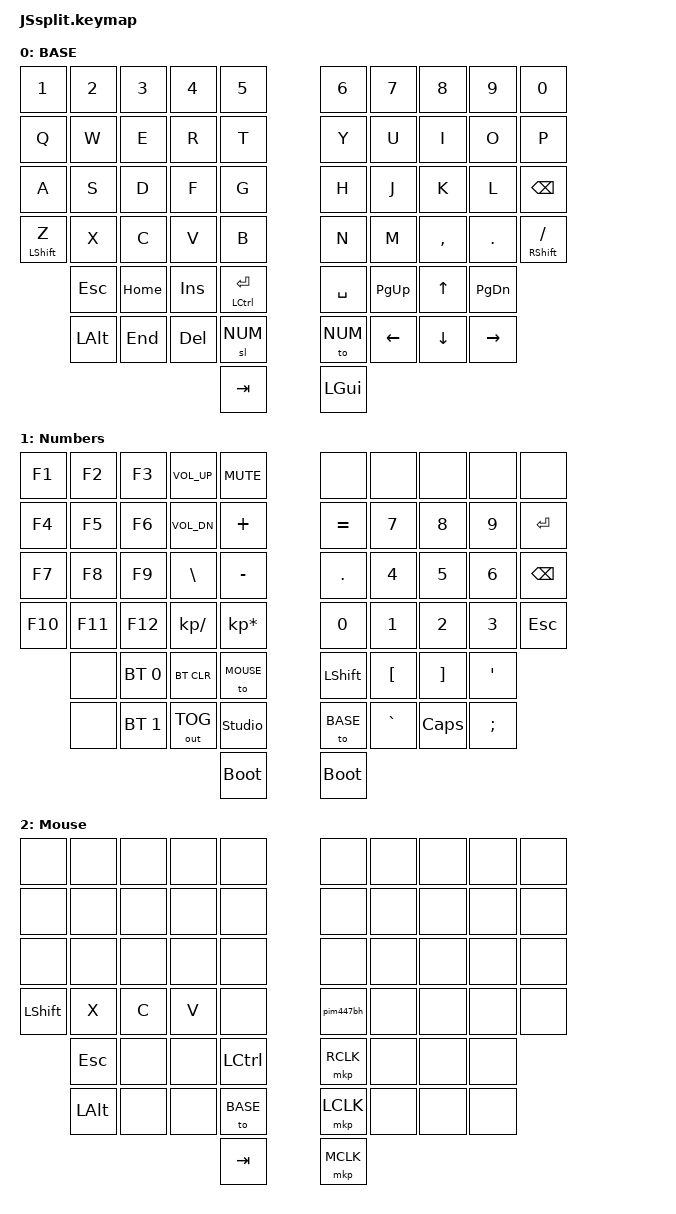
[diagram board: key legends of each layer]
#include <behaviors.dtsi>
#include <input/processors.dtsi>
#include <dt-bindings/zmk/keys.h>
#include <dt-bindings/zmk/bt.h>
#include <dt-bindings/zmk/outputs.h>
#include <dt-bindings/zmk/pointing.h>
#include <dt-bindings/zmk/mouse.h>
#include <dt-bindings/behavior_pim447.h>
//Need this include above for My Driver and not for New Driver (3-1-2026)

#define BASE 0
#define NUM 1
#define MOUSE 2
#define extra2 3

#define COMBO_TIME_OUT 25

/ {
    

   // My Driver -- pre 3-1-2026
   behaviors {
        pim447bh: pim447bh {
            compatible = "zmk,behavior-pim447";
            #binding-cells = <1>;
            action = <14>;
            
        };
        
    };

    /*
    //New Driver -- 3-1-2026
    behaviors {
        tb_mode: trackball_mode {
            compatible = "zmk,behavior-trackball-mode";
            #binding-cells = <1>;
            
            default-mode = <0>;    // 0=move, 1=scroll
            
            // Optional LED colors for each mode (see trackball_pim447.h)
            led-mode-move = <2>;   // Green (LED_GREEN) 
            led-mode-scroll = <3>; // Blue (LED_BLUE)
        };
    };
    */

    keymap {
        compatible = "zmk,keymap";

        /* Qwerty
        ┏━━━━━━━━━┳━━━━━━━━━┳━━━━━━━━━┳━━━━━━━━━┳━━━━━━━━━┓          ┏━━━━━━━━━┳━━━━━━━━━┳━━━━━━━━━┳━━━━━━━━━┳━━━━━━━━━┓
        ┃   1 !   ┃   2 @   ┃    3    ┃    4    ┃    5    ┃          ┃    6    ┃    7    ┃    8    ┃    9    ┃    0    ┃
        ┣━━━━━━━━━╋━━━━━━━━━╋━━━━━━━━━╋━━━━━━━━━╋━━━━━━━━━┫          ┣━━━━━━━━━╋━━━━━━━━━╋━━━━━━━━━╋━━━━━━━━━╋━━━━━━━━━┫
        ┃    Q    ┃    W    ┃    E    ┃    R    ┃    T    ┃          ┃    Y    ┃    U    ┃    I    ┃    O    ┃    P    ┃
        ┣━━━━━━━━━╋━━━━━━━━━╋━━━━━━━━━╋━━━━━━━━━╋━━━━━━━━━┫          ┣━━━━━━━━━╋━━━━━━━━━╋━━━━━━━━━╋━━━━━━━━━╋━━━━━━━━━┫
        ┃    A    ┃    S    ┃    D    ┃    F    ┃    G    ┃          ┃    H    ┃    J    ┃    K    ┃    L    ┃   BSPC  ┃
        ┣━━━━━━━━━╋━━━━━━━━━╋━━━━━━━━━╋━━━━━━━━━╋━━━━━━━━━┫          ┣━━━━━━━━━╋━━━━━━━━━╋━━━━━━━━━╋━━━━━━━━━╋━━━━━━━━━┫
        ┃SHIFT  Z ┃    X    ┃    C    ┃    V    ┃    B    ┃          ┃    N    ┃    M    ┃    ,    ┃    .    ┃SHIFT /  ┃
        ┗━━━━━━━━━╋━━━━━━━━━╋━━━━━━━━━╋━━━━━━━━━╋━━━━━━━━━┫          ┣━━━━━━━━━╋━━━━━━━━━╋━━━━━━━━━╋━━━━━━━━━╋━━━━━━━━━┛
                  ┃  WIN    ┃  HOME   ┃   INS   ┃CTRL/ENTR┃          ┃  SPACE  ┃  PG_UP  ┃    UP   ┃  PG_DN  ┃
                  ┣━━━━━━━━━╋━━━━━━━━━╋━━━━━━━━━╋━━━━━━━━━┫          ┣━━━━━━━━━╋━━━━━━━━━╋━━━━━━━━━╋━━━━━━━━━┫
                  ┃  LALT   ┃   END   ┃   DEL   ┃ TempNUM ┃          ┃ TO NUM  ┃   LEFT  ┃   DOWN  ┃  RIGHT  ┃
                  ┗━━━━━━━━━┻━━━━━━━━━┻━━━━━━━━━┣━━━━━━━━━┫          ┣━━━━━━━━━┫━━━━━━━━━┻━━━━━━━━━┻━━━━━━━━━┛
                                                ┃   TAB   ┃          ┃   ESC   ┃
                                                ┗━━━━━━━━━┛          ┗━━━━━━━━━┛
        */

        base {
            label = "BASE";
            bindings = <
                &kp N1      &kp N2      &kp N3          &kp N4          &kp N5                              &kp N6      &kp N7          &kp N8          &kp N9          &kp N0
                &kp Q       &kp W       &kp E           &kp R           &kp T                               &kp Y       &kp U           &kp I           &kp O           &kp P
                &kp A       &kp S       &kp D           &kp F           &kp G                               &kp H       &kp J           &kp K           &kp L           &kp BSPC
                &mt LSHFT Z &kp X       &kp C           &kp V           &kp B                               &kp N       &kp M           &kp COMMA       &kp DOT         &mt RSHFT FSLH
                            &kp ESC     &kp HOME        &kp INSERT      &mt LCTRL ENTER                     &kp SPACE   &kp PG_UP       &kp UP_ARROW    &kp PG_DN
                            &kp LALT    &kp END         &kp DELETE      &sl NUM                             &to NUM     &kp LEFT_ARROW  &kp DOWN_ARROW  &kp RIGHT_ARROW
                                                                        &kp TAB                             &kp LGUI
            >;
        };

        /* Numbers
        ┏━━━━━━━━━┳━━━━━━━━━┳━━━━━━━━━┳━━━━━━━━━┳━━━━━━━━━┓          ┏━━━━━━━━━┳━━━━━━━━━┳━━━━━━━━━┳━━━━━━━━━┳━━━━━━━━━┓
        ┃    F1   ┃    F2   ┃   F3    ┃  VOL+   ┃   MUTE  ┃          ┃  NONE   ┃  NONE   ┃  NONE   ┃  NONE   ┃  NONE   ┃
        ┣━━━━━━━━━╋━━━━━━━━━╋━━━━━━━━━╋━━━━━━━━━╋━━━━━━━━━┫          ┣━━━━━━━━━╋━━━━━━━━━╋━━━━━━━━━╋━━━━━━━━━╋━━━━━━━━━┫
        ┃    F4   ┃    F5   ┃    F6   ┃  VOL-   ┃    +    ┃          ┃   = +   ┃    7    ┃    8    ┃    9    ┃  ENTER  ┃
        ┣━━━━━━━━━╋━━━━━━━━━╋━━━━━━━━━╋━━━━━━━━━╋━━━━━━━━━┫          ┣━━━━━━━━━╋━━━━━━━━━╋━━━━━━━━━╋━━━━━━━━━╋━━━━━━━━━┫
        ┃    F7   ┃    F8   ┃    F9   ┃   \ |   ┃  - _    ┃          ┃    .    ┃    4    ┃    5    ┃    6    ┃   BSPC  ┃
        ┣━━━━━━━━━╋━━━━━━━━━╋━━━━━━━━━╋━━━━━━━━━╋━━━━━━━━━┫          ┣━━━━━━━━━╋━━━━━━━━━╋━━━━━━━━━╋━━━━━━━━━╋━━━━━━━━━┫
        ┃   F10   ┃   F11   ┃   F12   ┃    /    ┃    *    ┃          ┃    0    ┃    1    ┃    2    ┃    3    ┃   ESC   ┃
        ┗━━━━━━━━━╋━━━━━━━━━╋━━━━━━━━━╋━━━━━━━━━╋━━━━━━━━━┫          ┣━━━━━━━━━╋━━━━━━━━━╋━━━━━━━━━╋━━━━━━━━━╋━━━━━━━━━┛
                  ┃  NONE   ┃  NONE   ┃  NONE   ┃ TO BASE ┃          ┃  SHIFT  ┃   {     ┃     }   ┃    '    ┃
                  ┣━━━━━━━━━╋━━━━━━━━━╋━━━━━━━━━╋━━━━━━━━━┫          ┣━━━━━━━━━╋━━━━━━━━━╋━━━━━━━━━╋━━━━━━━━━┫
                  ┃  NONE   ┃  NONE   ┃  NONE   ┃  STUDIO ┃          ┃   BASE  ┃   ` ~   ┃   CAPS  ┃    ;    ┃
                  ┗━━━━━━━━━┻━━━━━━━━━┻━━━━━━━━━┣━━━━━━━━━┫          ┣━━━━━━━━━┫━━━━━━━━━┻━━━━━━━━━┻━━━━━━━━━┛
                                                ┃  BOOT   ┃          ┃   BOOT  ┃
                                                ┗━━━━━━━━━┛          ┗━━━━━━━━━┛
        */

        number {
            label = "Numbers";
            bindings = <
                &kp F1  &kp F2      &kp F3          &kp C_VOL_UP    &kp C_MUTE                          &none       &none           &none           &none           &none
                &kp F4  &kp F5      &kp F6          &kp C_VOL_DN    &kp PLUS                            &kp EQUAL   &kp N7          &kp N8          &kp N9          &kp ENTER
                &kp F7  &kp F8      &kp F9          &kp BSLH        &kp MINUS                           &kp DOT     &kp N4          &kp N5          &kp N6          &kp BSPC
                &kp F10 &kp F11     &kp F12         &kp KP_SLASH    &kp KP_ASTERISK                     &kp N0      &kp N1          &kp N2          &kp N3          &kp ESC
                        &none       &bt BT_SEL 0    &bt BT_CLR      &to MOUSE                           &kp LSHIFT  &kp LBKT        &kp RBKT        &kp SQT
                        &none       &bt BT_SEL 1    &out OUT_TOG    &studio_unlock                      &to BASE    &kp GRAVE       &kp CAPS        &kp SEMI
                                                                    &bootloader                         &bootloader
            >;
        };

        /* Mouse
        ┏━━━━━━━━━┳━━━━━━━━━┳━━━━━━━━━┳━━━━━━━━━┳━━━━━━━━━┓          ┏━━━━━━━━━┳━━━━━━━━━┳━━━━━━━━━┳━━━━━━━━━┳━━━━━━━━━┓
        ┃    F1   ┃    F2   ┃   F3    ┃  VOL+   ┃   MUTE  ┃          ┃  NONE   ┃  NONE   ┃  NONE   ┃  NONE   ┃  NONE   ┃
        ┣━━━━━━━━━╋━━━━━━━━━╋━━━━━━━━━╋━━━━━━━━━╋━━━━━━━━━┫          ┣━━━━━━━━━╋━━━━━━━━━╋━━━━━━━━━╋━━━━━━━━━╋━━━━━━━━━┫
        ┃    F4   ┃    F5   ┃    F6   ┃  VOL-   ┃    +    ┃          ┃   = +   ┃    7    ┃    8    ┃    9    ┃  ENTER  ┃
        ┣━━━━━━━━━╋━━━━━━━━━╋━━━━━━━━━╋━━━━━━━━━╋━━━━━━━━━┫          ┣━━━━━━━━━╋━━━━━━━━━╋━━━━━━━━━╋━━━━━━━━━╋━━━━━━━━━┫
        ┃    F7   ┃    F8   ┃    F9   ┃   \ |   ┃  - _    ┃          ┃    .    ┃    4    ┃    5    ┃    6    ┃   BSPC  ┃
        ┣━━━━━━━━━╋━━━━━━━━━╋━━━━━━━━━╋━━━━━━━━━╋━━━━━━━━━┫          ┣━━━━━━━━━╋━━━━━━━━━╋━━━━━━━━━╋━━━━━━━━━╋━━━━━━━━━┫
        ┃   F10   ┃   F11   ┃   F12   ┃    /    ┃    *    ┃          ┃    0    ┃    1    ┃    2    ┃    3    ┃   ESC   ┃
        ┗━━━━━━━━━╋━━━━━━━━━╋━━━━━━━━━╋━━━━━━━━━╋━━━━━━━━━┫          ┣━━━━━━━━━╋━━━━━━━━━╋━━━━━━━━━╋━━━━━━━━━╋━━━━━━━━━┛
                  ┃  NONE   ┃  NONE   ┃  NONE   ┃ TO BASE ┃          ┃  SHIFT  ┃   {     ┃     }   ┃    '    ┃
                  ┣━━━━━━━━━╋━━━━━━━━━╋━━━━━━━━━╋━━━━━━━━━┫          ┣━━━━━━━━━╋━━━━━━━━━╋━━━━━━━━━╋━━━━━━━━━┫
                  ┃  NONE   ┃  NONE   ┃  NONE   ┃  STUDIO ┃          ┃   BASE  ┃   ` ~   ┃   CAPS  ┃    ;    ┃
                  ┗━━━━━━━━━┻━━━━━━━━━┻━━━━━━━━━┣━━━━━━━━━┫          ┣━━━━━━━━━┫━━━━━━━━━┻━━━━━━━━━┻━━━━━━━━━┛
                                                ┃  BOOT   ┃          ┃   BOOT  ┃
                                                ┗━━━━━━━━━┛          ┗━━━━━━━━━┛
        */

        mouse {
            label = "Mouse"; 
            bindings = <
                &none       &none           &none           &none           &none                           &none       &none           &none           &none           &none
                &none       &none           &none           &none           &none                           &none       &none           &none           &none           &none
                &none       &none           &none           &none           &none                           &none       &none           &none           &none           &none
                &kp LSHFT   &kp X           &kp C           &kp V           &none                           &pim447bh       &none           &none           &none           &none
                            &kp ESC         &none           &none           &kp LCTRL                       &mkp RCLK   &none           &none           &none
                            &kp LALT        &none           &none           &to BASE                        &mkp LCLK   &none           &none           &none
                                                                            &kp TAB                         &mkp MCLK
            >;
        };

        extra2 {
            status = "reserved";
        };

    };
};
